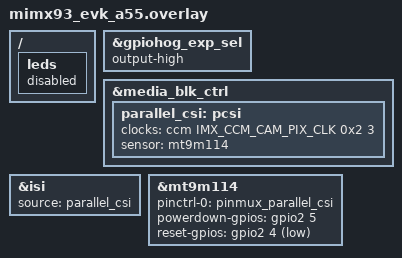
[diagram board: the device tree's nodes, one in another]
/*
 * Copyright 2023 NXP
 *
 * SPDX-License-Identifier: Apache-2.0
 */

/{
	leds {
        status = "disabled";
    };
};

&gpiohog_exp_sel {
    output-high;
};

&media_blk_ctrl {
	status = "okay";

	parallel_csi: pcsi {
		clocks = <&ccm IMX_CCM_CAM_PIX_CLK 0x2 3>;
		sensor = <&mt9m114>;
		status = "okay";
	};
};

&isi {
	status = "okay";
	source = <&parallel_csi>;
};

&mt9m114 {
	pinctrl-0 = <&pinmux_parallel_csi>;
	pinctrl-names = "default";
	powerdown-gpios = <&gpio2 5 GPIO_ACTIVE_HIGH>;
	reset-gpios = <&gpio2 4 GPIO_ACTIVE_LOW>;
};
